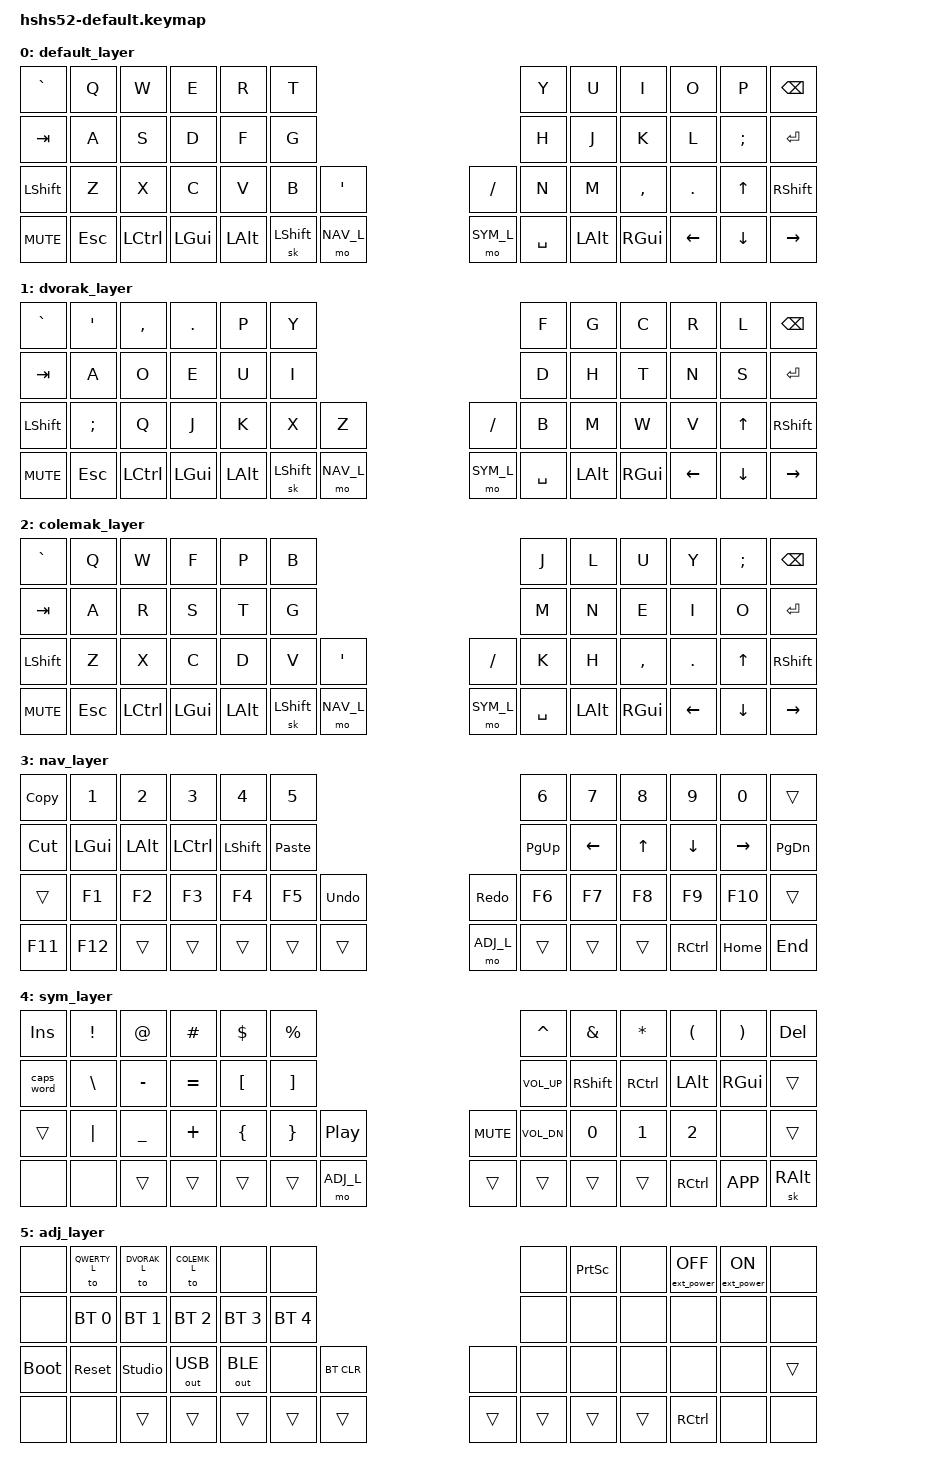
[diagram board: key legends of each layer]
/*
 * Copyright (c) 2021-2022 The ZMK Contributors
 *
 * SPDX-License-Identifier: MIT
 */

#include <behaviors.dtsi>
#include <physical_layouts.dtsi>
#include <dt-bindings/zmk/bt.h>
#include <dt-bindings/zmk/ext_power.h>
#include <dt-bindings/zmk/keys.h>
#include <dt-bindings/zmk/outputs.h>

#define QWERTY_L 0
#define DVORAK_L 1
#define COLEMK_L 2
#define NAV_L    3
#define SYM_L    4
#define ADJ_L    5

#define Undo   LC(Z)
#define Cut    LC(X)
#define Copy   LC(C)
#define Paste  LC(V)
#define Redo   LC(Y)


/ {
        chosen {
                zmk,physical-layout = &physical_layout0;
        };

        physical_layout0: physical_layout_0 {
                compatible = "zmk,physical-layout";
                display-name = "Default Layout";
                transform = <&default_transform>;
                kscan = <&kscan0>;
                                keys
                        /* Row 0 */
                        = <&key_physical_attrs 100 100       0   19210       0 0 0>
                        , <&key_physical_attrs 100 100   18000   15810       0 0 0>
                        , <&key_physical_attrs 100 100   37800    5270       0 0 0>
                        , <&key_physical_attrs 100 100   57600       0       0 0 0>
                        , <&key_physical_attrs 100 100   75600    4760       0 0 0>
                        , <&key_physical_attrs 100 100   93600    7140       0 0 0>
                        , <&key_physical_attrs 100 100  174600    7140       0 0 0>
                        , <&key_physical_attrs 100 100  192600    4760       0 0 0>
                        , <&key_physical_attrs 100 100  210600       0       0 0 0>
                        , <&key_physical_attrs 100 100  230400    5270       0 0 0>
                        , <&key_physical_attrs 100 100  250200   15810       0 0 0>
                        , <&key_physical_attrs 100 100  268200   19210       0 0 0>
                        /* Row 1 */
                        , <&key_physical_attrs 100 100    1800   36210       0 0 0>
                        , <&key_physical_attrs 100 100   19800   32810       0 0 0>
                        , <&key_physical_attrs 100 100   38700   22270       0 0 0>
                        , <&key_physical_attrs 100 100   57600   17000       0 0 0>
                        , <&key_physical_attrs 100 100   75600   21760       0 0 0>
                        , <&key_physical_attrs 100 100   93600   24140       0 0 0>
                        , <&key_physical_attrs 100 100  174600   24140       0 0 0>
                        , <&key_physical_attrs 100 100  192600   21760       0 0 0>
                        , <&key_physical_attrs 100 100  210600   17000       0 0 0>
                        , <&key_physical_attrs 100 100  229500   22270       0 0 0>
                        , <&key_physical_attrs 100 100  248400   32810       0 0 0>
                        , <&key_physical_attrs 100 100  266400   36210       0 0 0>
                        /* Row 2 */
                        , <&key_physical_attrs 100 100    3600   53210       0 0 0>
                        , <&key_physical_attrs 100 100   21600   49810       0 0 0>
                        , <&key_physical_attrs 100 100   39600   39270       0 0 0>
                        , <&key_physical_attrs 100 100   57600   34000       0 0 0>
                        , <&key_physical_attrs 100 100   75600   38760       0 0 0>
                        , <&key_physical_attrs 100 100   93600   41140       0 0 0>
                        , <&key_physical_attrs 100 100  111600   48960       0 0 0>
                        , <&key_physical_attrs 100 100  156600   48960       0 0 0>
                        , <&key_physical_attrs 100 100  174600   41140       0 0 0>
                        , <&key_physical_attrs 100 100  192600   38760       0 0 0>
                        , <&key_physical_attrs 100 100  210600   34000       0 0 0>
                        , <&key_physical_attrs 100 100  228600   39270       0 0 0>
                        , <&key_physical_attrs 100 100  246600   49810       0 0 0>
                        , <&key_physical_attrs 100 100  264600   53210       0 0 0>
                        /* Row 3 / Thumb Row */
                        , <&key_physical_attrs 100 100    5400   66810       0 0 0>
                        , <&key_physical_attrs 100 100   23400   66810       0 0 0>
                        , <&key_physical_attrs 100 100   41400   66810       0 0 0>
                        , <&key_physical_attrs 100 100   66600   55760       0 0 0> // Thumb Arc Left
                        , <&key_physical_attrs 100 100   84600   58140       0 0 0>
                        , <&key_physical_attrs 100 100  102600   65960       0 0 0>
                        , <&key_physical_attrs 100 100  120600   75480       0 0 0>
                        , <&key_physical_attrs 100 100  147600   75480       0 0 0> // Thumb Arc Right
                        , <&key_physical_attrs 100 100  165600   65960       0 0 0>
                        , <&key_physical_attrs 100 100  183600   58140       0 0 0>
                        , <&key_physical_attrs 100 100  201600   55760       0 0 0>
                        , <&key_physical_attrs 100 100  226800   66810       0 0 0>
                        , <&key_physical_attrs 100 100  244800   66810       0 0 0>
                        , <&key_physical_attrs 100 100  262800   66810       0 0 0>
                        ;
        };

        keymap {
                compatible = "zmk,keymap";

                default_layer {
/* QWERTY
 * -------------------------------------------------------------------------------------------------------------------------------------
 * | `     |   Q   |   W   |   E   |   R   |   T   |-----------------------------------|   Y   |   U   |   I   |   O   |   P   | BKSPC |
 * | TAB   |   A   |   S   |   D   |   F   |   G   |-----------------------------------|   H   |   J   |   K   |   L   |   ;   | ENTER |
 * | SHIFT |   Z   |   X   |   C   |   V   |   B   |   '   |-------------------|   /   |   N   |   M   |   ,   |   .   |  Up   | SHIFT |
 * | Mute  |  ESC  | CTRL  |-------|  GUI  |  ALT  |SK SHFT|  Nav  |---|  Sym  | SPACE |  ALT  |  GUI  |-------| Left  | Down  | Right |
 */
                        bindings = <
&kp  GRAVE    &kp  Q        &kp  W        &kp  E        &kp  R        &kp  T                                                                         &kp  Y        &kp  U        &kp  I        &kp  O        &kp  P        &kp  BSPC
&kp  TAB      &kp  A        &kp  S        &kp  D        &kp  F        &kp  G                                                                         &kp  H        &kp  J        &kp  K        &kp  L        &kp  SEMI     &kp  ENTER
&kp  LSHFT    &kp  Z        &kp  X        &kp  C        &kp  V        &kp  B        &kp  SQT                                           &kp  SLASH    &kp  N        &kp  M        &kp  COMMA    &kp  DOT      &kp  UP       &kp  RSHFT
&kp  C_MUTE   &kp  ESC      &kp  LCTRL                  &kp  LGUI     &kp  LALT     &sk  LSHIFT    &mo  NAV_L            &mo  SYM_L    &kp  SPACE    &kp  LALT     &kp  RGUI                   &kp  LEFT     &kp  DOWN     &kp  RIGHT
                        >;

                        sensor-bindings = <&inc_dec_kp C_VOL_UP C_VOL_DN &inc_dec_kp PG_UP PG_DN>;
                };

                dvorak_layer {
/* DVORAK
 * -------------------------------------------------------------------------------------------------------------------------------------
 * | `     |   '   |   ,   |   .   |   P   |   Y   |-----------------------------------|   F   |   G   |   C   |   R   |   L   | BKSPC |
 * | TAB   |   A   |   O   |   E   |   U   |   I   |-----------------------------------|   D   |   H   |   T   |   N   |   S   | ENTER |
 * | SHIFT |   ;   |   Q   |   J   |   K   |   X   |   Z   |-------------------|   /   |   B   |   M   |   W   |   V   |  Up   | SHIFT |
 * | Mute  |  ESC  | CTRL  |-------|  GUI  |  ALT  |SK SHFT|  Nav  |---|  Sym  | SPACE |  ALT  |  GUI  |-------| Left  | Down  | Right |
 */
                        bindings = <
&kp  GRAVE    &kp  SQT      &kp  COMMA    &kp  DOT      &kp  P        &kp  Y                                                                         &kp  F        &kp  G        &kp  C        &kp  R        &kp  L        &kp  BSPC
&kp  TAB      &kp  A        &kp  O        &kp  E        &kp  U        &kp  I                                                                         &kp  D        &kp  H        &kp  T        &kp  N        &kp  S        &kp  ENTER
&kp  LSHFT    &kp  SEMI     &kp  Q        &kp  J        &kp  K        &kp  X        &kp  Z                                             &kp  SLASH    &kp  B        &kp  M        &kp  W        &kp  V        &kp  UP       &kp  RSHFT
&kp  C_MUTE   &kp  ESC      &kp  LCTRL                  &kp  LGUI     &kp  LALT     &sk  LSHIFT    &mo  NAV_L            &mo  SYM_L    &kp  SPACE    &kp  LALT     &kp  RGUI                   &kp  LEFT     &kp  DOWN     &kp  RIGHT
                        >;

                        sensor-bindings = <&inc_dec_kp C_VOL_UP C_VOL_DN &inc_dec_kp PG_UP PG_DN>;
                };

                colemak_layer {
/* COLEMAK-DH
 * -------------------------------------------------------------------------------------------------------------------------------------
 * | `     |   Q   |   W   |   F   |   P   |   B   |-----------------------------------|   J   |   L   |   U   |   Y   |   ;   | BKSPC |
 * | TAB   |   A   |   R   |   S   |   T   |   G   |-----------------------------------|   M   |   N   |   E   |   I   |   O   | ENTER |
 * | SHIFT |   Z   |   X   |   C   |   D   |   V   |   '   |-------------------|   /   |   K   |   H   |   ,   |   .   |  Up   | SHIFT |
 * | Mute  |  ESC  | CTRL  |-------|  GUI  |  ALT  |SK SHFT|  Nav  |---|  Sym  | SPACE |  ALT  |  GUI  |-------| Left  | Down  | Right |
 */
                        bindings = <
&kp  GRAVE    &kp  Q        &kp  W        &kp  F        &kp  P        &kp  B                                                                         &kp  J        &kp  L        &kp  U        &kp  Y        &kp  SEMI     &kp  BSPC
&kp  TAB      &kp  A        &kp  R        &kp  S        &kp  T        &kp  G                                                                         &kp  M        &kp  N        &kp  E        &kp  I        &kp  O        &kp  ENTER
&kp  LSHFT    &kp  Z        &kp  X        &kp  C        &kp  D        &kp  V        &kp  SQT                                           &kp  SLASH    &kp  K        &kp  H        &kp  COMMA    &kp  DOT      &kp  UP       &kp  RSHFT
&kp  C_MUTE   &kp  ESC      &kp  LCTRL                  &kp  LGUI     &kp  LALT     &sk  LSHIFT     &mo  NAV_L           &mo  SYM_L    &kp  SPACE    &kp  LALT     &kp  RGUI                   &kp  LEFT     &kp  DOWN     &kp  RIGHT
                        >;

                        sensor-bindings = <&inc_dec_kp C_VOL_UP C_VOL_DN &inc_dec_kp PG_UP PG_DN>;
                };

                nav_layer {
/* NAV
 * -------------------------------------------------------------------------------------------------------------------------------------
 * | Copy  |   1   |   2   |   3   |   4   |   5   |-----------------------------------|   6   |   7   |   8   |   9   |   0   | BSPC  |
 * | Cut   |  GUI  |  Alt  | Ctrl  | Shift | Paste |-----------------------------------| PG UP |  Left |  Up   |  Down | Right | PG DN |
 * | Shift |  F1   |  F2   |  F3   |  F4   |  F5   |  UnDo |-------------------| ReDo  |  F6   |  F7   |  F8   |  F9   |  F10  | Shift |
 * | F11   |  F12  |       |-------|       |       |       |       |---| ADJ_L |       |       |       |-------| CTRL  | HOME  |  END  |
 */
                        bindings = <
&kp  Copy     &kp  N1       &kp  N2       &kp  N3       &kp  N4       &kp  N5                                                                        &kp   N6      &kp  N7      &kp   N8      &kp   N9      &kp  N0       &trans
&kp  Cut      &kp  LGUI     &kp  LALT     &kp  LCTRL    &kp  LSHFT    &kp  Paste                                                                     &kp   PG_UP   &kp  LEFT    &kp   UP      &kp   DOWN    &kp  RIGHT    &kp PG_DN
&trans        &kp  F1       &kp  F2       &kp  F3       &kp  F4       &kp  F5       &kp Undo                                           &kp  Redo     &kp   F6      &kp  F7      &kp   F8      &kp   F9      &kp  F10      &trans
&kp  F11      &kp  F12      &trans                      &trans        &trans        &trans        &trans                 &mo ADJ_L     &trans        &trans        &trans                     &kp  RCTRL    &kp  HOME     &kp  END
                        >;

                        sensor-bindings = <&inc_dec_kp PG_UP PG_DN &inc_dec_kp C_VOL_UP C_VOL_DN>;
                };

                sym_layer {
/* SYM
 * -------------------------------------------------------------------------------------------------------------------------------------
 * | INS   |   !   |   @   |   #   |   $   |   %   |-----------------------------------|   ^   |   &   |   *   |   (   |   )   | DELETE|
 * | CAPS  |   \   |   -   |   =   |   [   |   ]   |-----------------------------------| Vol+  | Shift | Ctrl  | Alt   | Gui   | ENTER |
 * | Shift |   |   |   _   |   +   |   {   |   }   | Play  |-------------------| Mute  | Vol-  |  N0   |  N1   |  N2   |       | SHIFT |
 * |       |       |       |-------|       |       |       |  ADJ_L |---|      |       |       |       |-------| CTRL  | MENU  |SkAltGr|
 */
                        bindings = <
&kp  INS      &kp  EXCL     &kp  AT       &kp  HASH     &kp  DOLLAR   &kp  PERCENT                                                                   &kp  CARET    &kp  AMPS     &kp  ASTRK    &kp  LPAR     &kp  RPAR     &kp  DEL
&caps_word    &kp  BSLH     &kp  MINUS    &kp  EQUAL    &kp  LBKT     &kp  RBKT                                                                      &kp C_VOL_UP  &kp  RSHFT    &kp  RCTRL    &kp  LALT     &kp  RGUI     &trans
&trans        &kp  PIPE     &kp  UNDER    &kp  PLUS     &kp  LBRC     &kp  RBRC     &kp  C_PP                                          &kp C_MUTE    &kp C_VOL_DN  &kp  N0       &kp  N1       &kp  N2       &none         &trans
&none         &none         &trans                      &trans        &trans        &trans        &mo  ADJ_L               &trans      &trans        &trans        &trans                      &kp  RCTRL    &kp  K_APP    &sk  RALT
                        >;

                        sensor-bindings = <&inc_dec_kp PG_UP PG_DN &inc_dec_kp C_VOL_UP C_VOL_DN>;
                };


                adj_layer {
/* ADJUST
 * -------------------------------------------------------------------------------------------------------------------------------------
 * |       | QWERTY| DVORAK| COLEMK|       |       |-----------------------------------|       |Prt Scr|       | EP_OFF| EP_ON |       |
 * |       | BT 0  | BT 1  | BT 2  | BT 3  | BT 4  |-----------------------------------|       |       |       |       |       |       |
 * | BOOTL | RESET | STUDIO|OUT_USB|OUT_BLE|       |BT CLR |-------------------|       |       |       |       |       |       | SHIFT |
 * ----------------|       |-------|       |       |       |       |---|       |       |       |       |-------| CTRL  |----------------
 */
                        bindings = <
&none         &to  QWERTY_L &to  DVORAK_L &to  COLEMK_L &none         &none                                                                             &none             &kp PRINTSCREEN    &none         &ext_power EP_OFF  &ext_power EP_ON &none
&none         &bt  BT_SEL 0 &bt  BT_SEL 1 &bt  BT_SEL 2 &bt  BT_SEL 3 &bt  BT_SEL 4                                                                     &none             &none              &none            &none           &none            &none
&bootloader   &sys_reset        &studio_unlock 	&out OUT_USB  &out OUT_BLE  &none         &bt BT_CLR                                         &none            &none             &none              &none            &none           &none            &trans
&none         &none         &trans                      &trans        &trans        &trans        &trans                 &trans        &trans           &trans            &trans                              &kp  RCTRL      &none            &none
                        >;

                        sensor-bindings = <&inc_dec_kp C_VOL_UP C_VOL_DN &inc_dec_kp PG_UP PG_DN>;
                };
        };
};
